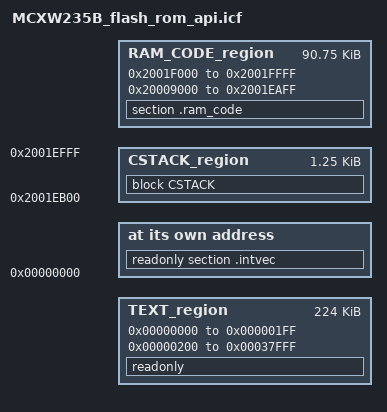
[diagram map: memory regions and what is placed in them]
/*
** ###################################################################
**     Processors:          MCXW235BIHNAR
**                          MCXW235BIUKAR
**
**     Compiler:            IAR ANSI C/C++ Compiler for ARM
**
**
**     Copyright 2016 Freescale Semiconductor, Inc.
**     Copyright 2016-2024 NXP
**     SPDX-License-Identifier: BSD-3-Clause
**
**     http:                 www.nxp.com
**     mail:                 support@nxp.com
**
** ###################################################################
*/

/* Stack and Heap Sizes */
if (isdefinedsymbol(__stack_size__)) {
  define symbol __size_cstack__        = __stack_size__;
} else {
  define symbol __size_cstack__        = 0x0500;
}

if (isdefinedsymbol(__heap_size__)) {
  define symbol __size_heap__          = __heap_size__;
} else {
  define symbol __size_heap__          = 0x0400;
}

define symbol m_interrupts_start               = 0x00000000;
define symbol m_interrupts_end                 = 0x000001FF;

define symbol m_text_start                     = 0x00000200;
define symbol m_text_end                       = 0x00037FFF;

/* 112k (SRAM0 = 16k, SRAM1 = 32k, SRAM2 = 64K) RAM to fit data segment */
/* First 16K (from 0x20004000 until 0x20008000) ram should should not be used because is used by ROM API functions */
/* Next 4K (from 0x20008000 until 0x20009000), ram should not be used because it is used by mbedTLS ROM functions */
/* Next 88K (from 0x20009000 until 0x2001F000)*, ram is used for data memory */
/* Last 4K (from 0x2001F000 until 0x20020000) ram is used to put code (typically interrupts, because interrupts cannot be executed from flash while flash IAP functions are executed)*/
define symbol m_data_start                     = 0x20009000;
define symbol m_data_end                       = 0x2001EFFF;

/* Create a RAM section that can be used to place code (typically interrupts, because interrupts cannot be executed from flash while flash IAP functions are executed)*/
define symbol m_ram_code_start                     = 0x2001F000;
define symbol m_ram_code_end                       = 0x2001FFFF;

define symbol m_sramx_start                    = 0x04000000;
define symbol m_sramx_end                      = 0x04003FFF;

define memory mem with size = 4G;

define region TEXT_region             = mem:[from m_interrupts_start to m_interrupts_end]
                                      | mem:[from m_text_start to m_text_end];                                 
define region RAM_CODE_region             = mem:[from m_ram_code_start to m_ram_code_end]                                      
define region DATA_region = mem:[from m_data_start to m_data_end-__size_cstack__];
define region CSTACK_region = mem:[from m_data_end-__size_cstack__+1 to m_data_end];
if (isdefinedsymbol(__use_shmem__)) {
  define region rpmsg_sh_mem_region     = mem:[from rpmsg_sh_mem_start to rpmsg_sh_mem_end];
}

define block CSTACK    with alignment = 8, size = __size_cstack__   { };
define block HEAP      with alignment = 8, size = __size_heap__     { };
define block RW        { readwrite };
define block ZI        { zi };


initialize by copy { readwrite, section .textrw };

if (isdefinedsymbol(__USE_DLIB_PERTHREAD))
{
  /* Required in a multi-threaded application */
  initialize by copy with packing = none { section __DLIB_PERTHREAD };
}

do not initialize  { section .noinit };
if (isdefinedsymbol(__use_shmem__)) {
  do not initialize  { section rpmsg_sh_mem_section };
}

place at address mem: m_interrupts_start    { readonly section .intvec };
place in TEXT_region                        { readonly };
place in RAM_CODE_region                    { section .ram_code };
place in DATA_region                        { block RW };
place in DATA_region                        { block ZI };
place in DATA_region                        { last block HEAP };
place in CSTACK_region                      { block CSTACK };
